AUTOSAR XML (schema 4-2-2)
package /Components
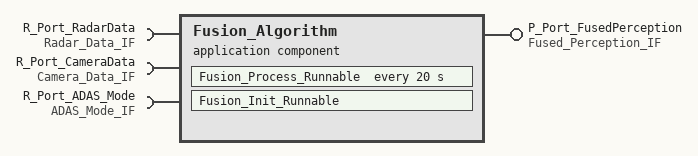
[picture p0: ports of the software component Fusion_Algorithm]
  application sw component type Fusion_Algorithm
    provide port P_Port_FusedPerception: provided-interface=Fused_Perception_IF
    require port R_Port_RadarData: required-interface=Radar_Data_IF
    require port R_Port_CameraData: required-interface=Camera_Data_IF
    require port R_Port_ADAS_Mode: required-interface=ADAS_Mode_IF
    behavior Fusion_Algorithm_InternalBehavior
      init event Fusion_Init_Event: start-on-event=Fusion_Init_Runnable
      swc mode switch event Fusion_Mode_Switch_Event: start-on-event=Fusion_Process_Runnable, activation=ON-TRANSITION
        mode:
          R_Port_ADAS_Mode.ADAS_ModeGroup.ACC_Mode
          R_Port_ADAS_Mode.ADAS_ModeGroup.LKA_Mode
          R_Port_ADAS_Mode.ADAS_ModeGroup.AEB_Mode
      timing event Fusion_Process_Event: start-on-event=Fusion_Process_Runnable, period=20
      runnable Fusion_Init_Runnable: symbol=Fusion_Init
        parameter access PA_Init_Fusion_Params: accessed-parameter=R_Port_RadarData.Radar_PointCloud
      runnable Fusion_Process_Runnable: minimum-start-interval=20, symbol=Fusion_Process
        data-receive-point-by-arguments:
          4 x access:
            VA_Recv_Radar_PointCloud: accessed-variable=R_Port_RadarData.Radar_PointCloud
            VA_Recv_Radar_Tracks: accessed-variable=R_Port_RadarData.Radar_Tracks
            VA_Recv_Camera_LaneModel: accessed-variable=R_Port_CameraData.Camera_LaneModel
            VA_Recv_Camera_ObjectList: accessed-variable=R_Port_CameraData.Camera_ObjectList
        data-send-points:
          access VA_Send_Fused_ObjectList: accessed-variable=P_Port_FusedPerception.Fused_ObjectList
          access VA_Send_Ego_State: accessed-variable=P_Port_FusedPerception.Ego_State
        parameter access PA_Run_Fusion_Params_Threshold: accessed-parameter=R_Port_CameraData.Fused_ObjectList
